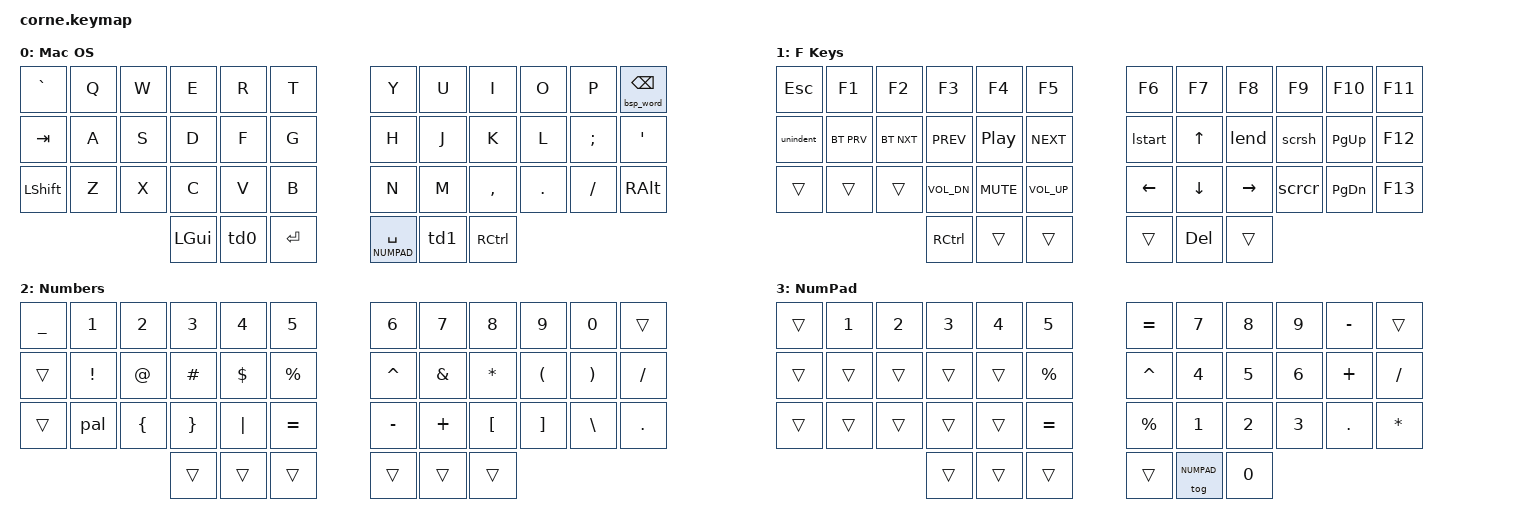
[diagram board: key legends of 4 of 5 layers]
/*
 * Copyright (c) 2023 The ZMK Contributors
 *
 * SPDX-License-Identifier: MIT
 */

#include <behaviors.dtsi>
#include <dt-bindings/zmk/keys.h>
#include <dt-bindings/zmk/bt.h>
#include <dt-bindings/zmk/outputs.h>


#define MACOS     0
#define FKEYS     1
#define NUMBERS   2
#define NUMPAD    3
#define KB_CONFIG 4


/ {

    behaviors {
        // Toggle F-Keys Layer
        td0: tap_dance_0 {
            compatible = "zmk,behavior-tap-dance";
            #binding-cells = <0>;
            tapping-term-ms = <300>;
            bindings = <&mo FKEYS>, <&tog FKEYS>, <&tog KB_CONFIG>;
        };
        // Toggle Numbers layer
        td1: tap_dance_1 {
            compatible = "zmk,behavior-tap-dance";
            #binding-cells = <0>;
            tapping-term-ms = <300>;
            bindings = <&mo NUMBERS>, <&tog NUMPAD>, <&tog NUMBERS>;
        };
        // Backspace a whole word when holding backspace
        backspace_word: backspace_word {
            compatible = "zmk,behavior-hold-tap";
            #binding-cells = <2>;
            tapping_term_ms = <250>;
            quick_tap_ms = <0>;
            flavor = "tap-preferred";
            bindings = <&bsp_word>, <&kp>;
        };
        //Mac OS word seek
        mac_word_seek: mac_word_seek {
            compatible = "zmk,behavior-sensor-rotate";
            #sensor-binding-cells = <0>;
            bindings = <&prev_word>, <&next_word>;
        };
    };


    macros {
        unindent: unindent {
            compatible = "zmk,behavior-macro";
            #binding-cells = <0>;
            bindings
                = <&macro_press &kp LSHIFT>
                , <&macro_tap &kp TAB>
                , <&macro_release &kp LSHIFT>
                ;
        };
        lstart: lstart {
            compatible = "zmk,behavior-macro";
            #binding-cells = <0>;
            bindings
                = <&macro_press &kp LGUI>
                , <&macro_tap &kp LEFT>
                , <&macro_release &kp LGUI>
                ;
        };
        lend: lend {
            compatible = "zmk,behavior-macro";
            #binding-cells = <0>;
            bindings
                = <&macro_press &kp LGUI>
                , <&macro_tap &kp RIGHT>
                , <&macro_release &kp LGUI>
                ;
        };
        scrsh: scrsh {
            compatible = "zmk,behavior-macro";
            #binding-cells = <0>;
            bindings
                = <&macro_press &kp LGUI>
                , <&macro_press &kp LSHIFT>
                , <&macro_tap &kp N3>
                , <&macro_release &kp LSHFT>
                , <&macro_release &kp LGUI>
                ;
        };
        scrcr: scrcr {
            compatible = "zmk,behavior-macro";
            #binding-cells = <0>;
            bindings
                = <&macro_press &kp LGUI>
                , <&macro_press &kp LSHIFT>
                , <&macro_tap &kp N5>
                , <&macro_release &kp LSHFT>
                , <&macro_release &kp LGUI>
                ;
        };
        pal: pal {
            compatible = "zmk,behavior-macro";
            #binding-cells = <0>;
            bindings
                = <&macro_press &kp LGUI>
                , <&macro_press &kp LCTRL>
                , <&macro_tap &kp SPACE>
                , <&macro_release &kp LCTRL>
                , <&macro_release &kp LGUI>
                ;
        };
        // Word backspace macros
        bsp_word: bsp_word {
            compatible = "zmk,behavior-macro";
            #binding-cells = <0>;
            bindings
                = <&macro_press &kp LALT>
                , <&macro_tap &kp BSPC>
                , <&macro_release &kp LALT>
                ;
        };
        // Word seek macros
        prev_word: prev_word {
            compatible = "zmk,behavior-macro";
            wait-ms = <2>;
            tap-ms = <20>;
            #binding-cells = <0>;
            bindings
                = <&macro_press &kp LALT>
                , <&macro_tap &kp LEFT>
                , <&macro_release &kp LALT>
                ;
        };
        next_word: next_word {
            compatible = "zmk,behavior-macro";
            wait-ms = <2>;
            tap-ms = <20>;
            #binding-cells = <0>;
            bindings
                = <&macro_press &kp LALT>
                , <&macro_tap &kp RIGHT>
                , <&macro_release &kp LALT>
                ;
        };
    };


    keymap {
        compatible = "zmk,keymap";

        default_layer {
            display-name = "Mac OS";
            bindings = <
//---------------------------------------------------------------+                                 +---------------------------------------------------------------//
//          |         |          |           |          |        |                                 |       |       |           |         |          |           // 
  &kp GRAVE   &kp Q     &kp W      &kp E        &kp R     &kp T                                      &kp Y   &kp U     &kp I      &kp O     &kp P     &backspace_word 0 BSPC
//          |         |          |           |          |        |                                 |       |       |           |         |          |           //
  &kp TAB     &kp A     &kp S      &kp D        &kp F     &kp G                                      &kp H   &kp J     &kp K      &kp L    &kp SEMI    &kp SQT
//          |         |          |           |          |        +-----------+   +-----------------|       |       |           |         |          |           //
  &kp LSHIFT  &kp Z     &kp X      &kp C        &kp V     &kp B                                      &kp N   &kp M   &kp COMMA   &kp DOT    &kp FSLH   &kp RALT
//--------------------|          |           |          |        |           |   |                 |       |       |           |--------------------------------//  
                                               &kp LGUI     &td0     &kp ENTER      &lt NUMPAD SPACE   &td1  &kp RCTRL   
//                    +----------|-----------|----------|--------------------+   +-----------------|-------|--------|-----------|---------+                      //
            >;
        };

        f_keys_layer {
            display-name = "F Keys";
            bindings = <
//-------------------------------------------------------------------------------+                           +-------------------------------------------------------------------//
//          |            |            |              |            |              |                           |          |          |           |         |           |           // 
  &kp ESCAPE    &kp F1      &kp F2       &kp F3          &kp F4        &kp F5                                   &kp F6    &kp F7      &kp F8     &kp F9    &kp F10     &kp F11
//          |            |            |              |            |              |                           |          |          |           |         |           |           // 
  &unindent   &bt BT_PRV   &bt BT_NXT   &kp C_PREV     &kp C_PP     &kp C_NEXT                                 &lstart     &kp UP     &lend      &scrsh    &kp PG_UP   &kp F12
//          |            |            |              |            |              +-------------+    +--------+          |          |           |         |           |           // 
    &trans      &trans       &trans     &kp C_VOL_DN   &kp C_MUTE   &kp C_VOL_UP                               &kp LEFT   &kp DOWN   &kp RIGHT   &scrcr    &kp PG_DN   &kp F13
//-----------------------|            |              |            |              |             |    |        |          |          |           |         |-----------------------//  
                                                       &kp RCTRL       &trans        &trans            &trans    &kp DEL    &trans           
//                       +------------|--------------|------------|--------------|-------------+    +--------|----------|----------|-----------|---------+                       //
            >;

        };

        numbers_layer {
            display-name = "Numbers";
            bindings = <
//-------------------------------------------------------------------------------+                      +----------------------------------------------------------------------------//
//          |          |                |                 |          |           |                      |           |               |          |          |               |          // 
  &kp UNDER    &kp N1        &kp N2           &kp N3         &kp N4     &kp N5                             &kp N6        &kp N7        &kp N8     &kp N9       &kp N0        &trans
//          |          |                |                 |          |           |                      |           |               |          |          |               |          // 
    &trans    &kp EXCL       &kp AT          &kp HASH       &kp DLLR   &kp PRCNT                          &kp CARET   &kp AMPERSAND   &kp STAR   &kp LPAR     &kp RPAR      &kp FSLH
//          |          |                |                 |          |           +--------+     +-------|           |               |                     |               |          // 
   &trans       &pal     &kp LEFT_BRACE   &kp RIGHT_BRACE   &kp PIPE   &kp EQUAL                          &kp MINUS     &kp PLUS      &kp LBKT   &kp RBKT   &kp BACKSLASH   &kp DOT
//---------------------|                |                 |          |           |        |    |                    |               |          |          |--------------------------//
                                                             &trans     &trans      &trans       &trans     &trans       &trans     
//                     +----------------|-----------------|----------|-----------|--------+    +--------|----------|----------------|----------|----------+                          //
            >;
        };


        numpad_layer {
            display-name = "NumPad";
            bindings = <
//-----------------------------------------------------------------+                        +----------------------------------------------------------------------------//
//          |          |          |          |          |          |                        |           |               |          |          |               |          // 
    &trans     &kp N1     &kp N2     &kp N3     &kp N4     &kp N5                             &kp EQUAL      &kp N7        &kp N8     &kp N9     &kp MINUS      &trans
//          |          |          |          |          |          |                        |           |               |          |          |               |          // 
    &trans     &trans     &trans     &trans     &trans    &kp PRCNT                           &kp CARET      &kp N4        &kp N5     &kp N6     &kp PLUS      &kp FSLH
//          |          |          |          |          |          +--------+     +---------|           |               |          |          |               |          // 
    &trans     &trans      &trans     &trans     &trans    &kp EQUAL                           &kp PRCNT      &kp N1        &kp N2     &kp N3      &kp DOT      &kp STAR
//---------------------|          |          |          |          |        |     |         |           |               |          |          |--------------------------//
                                                &trans     &trans    &trans         &trans   &tog NUMPAD     &kp N0       
//                     +----------|----------|----------|----------|--------+     +---------|-----------|---------------|----------|----------+                          //
            >;
      };

        settings_layer {
            display-name = "Settings";
            bindings = <
//---------------------------------------------------------------------------------------+                        +------------------------------------------------------------------//
//          |              |              |              |              |                |                        |          |          |          |          |          |           // 
 &out OUT_TOG &bt BT_SEL 0   &bt BT_SEL 1   &bt BT_SEL 2   &bt BT_SEL 3    &bt BT_SEL 4                              &trans     &trans     &trans     &trans     &trans     &trans
//          |              |              |              |              |                |                        |          |          |          |          |          |           // 
    &trans     &bt BT_PRV     &bt BT_NXT       &trans         &trans         &trans                                  &trans     &trans     &trans     &trans     &trans     &trans
//          |              |              |              |              |                +--------+     +---------|          |          |          |          |          |           // 
    &trans       &trans       &bt BT_CLR       &trans         &trans         &trans                                 &trans     &trans     &trans     &trans     &trans
//-------------------------|              |              |              |                |        |     |         |          |          |          |          |----------------------//
                                                              &trans      &tog KB_CONFIG   &trans         &trans     &trans     &trans   
//                         +--------------|--------------|--------------|----------------|--------+     +----------|---------|----------|----------|----------+                      //
            >;
        };

    };
};
